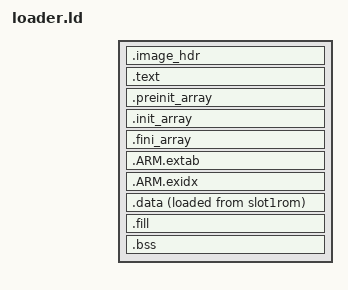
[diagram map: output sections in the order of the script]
INCLUDE memory_map.ld

/* Enforce emmition of the vector table. */
EXTERN (vector_table)

/* Define the entry point of the output file. */
ENTRY(reset_handler)

/* Define sections. */
SECTIONS
{
    .image_hdr : {
        KEEP (*(.image_hdr))
    } > slot1rom

    /* Vector table must be 128-bit aligned */
    . = ALIGN(128);

	.text : {
		*(.vectors)	/* Vector table */
		*(.text*)	/* Program code */
		. = ALIGN(4);
		*(.rodata*)	/* Read-only data */
		. = ALIGN(4);
	} >slot1rom

	/* C++ Static constructors/destructors, also used for __attribute__
	 * ((constructor)) and the likes */
	.preinit_array : {
		. = ALIGN(4);
		__preinit_array_start = .;
		KEEP (*(.preinit_array))
		__preinit_array_end = .;
	} >slot1rom
	.init_array : {
		. = ALIGN(4);
		__init_array_start = .;
		KEEP (*(SORT(.init_array.*)))
		KEEP (*(.init_array))
		__init_array_end = .;
	} >slot1rom
	.fini_array : {
		. = ALIGN(4);
		__fini_array_start = .;
		KEEP (*(.fini_array))
		KEEP (*(SORT(.fini_array.*)))
		__fini_array_end = .;
	} >slot1rom

	/*
	 * Another section used by C++ stuff, appears when using newlib with
	 * 64bit (long long) printf support
	 */
	.ARM.extab : {
		*(.ARM.extab*)
	} >slot1rom
	.ARM.exidx : {
		__exidx_start = .;
		*(.ARM.exidx*)
		__exidx_end = .;
	} >slot1rom

	. = ALIGN(4);
	_etext = .;

	.data : {
		_data = .;
		*(.data*)	/* Read-write initialized data */
		. = ALIGN(4);
		_edata = .;
	} >ram AT >slot1rom
	_data_loadaddr = LOADADDR(.data);

    .fill : {
        FILL(0xFF);
        . = ORIGIN(slot1rom) + LENGTH(slot1rom) - 1;
        BYTE(0xFF);
    } >slot1rom

	.bss : {
		*(.bss*)	/* Read-write zero initialized data */
		*(COMMON)
		. = ALIGN(4);
		_ebss = .;
	} >ram

	/*
	 * The .eh_frame section appears to be used for C++ exception handling.
	 * You may need to fix this if you're using C++.
	 */
	/DISCARD/ : { *(.eh_frame) }

	. = ALIGN(4);
	end = .;
}

PROVIDE(_stack = ORIGIN(ram) + LENGTH(ram));
